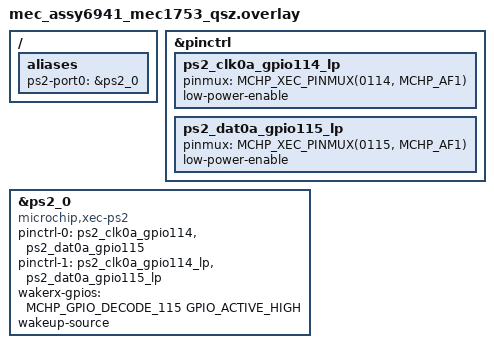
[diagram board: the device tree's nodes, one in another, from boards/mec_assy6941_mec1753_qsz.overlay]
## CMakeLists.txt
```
# SPDX-License-Identifier: Apache-2.0

cmake_minimum_required(VERSION 3.28.0)
find_package(Zephyr REQUIRED HINTS $ENV{ZEPHYR_BASE})
project(espi)

FILE(GLOB app_sources src/*.c)
target_sources(app PRIVATE ${app_sources})
```

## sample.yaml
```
sample:
  name: PS2 driver  sample
tests:
  sample.drivers.espi.ps2:
    tags:
      - drivers
      - ps2
    integration_platforms:
      - mec172xmodular_assy6930
    harness: console
    harness_config:
      type: multi_line
      ordered: true
      regex:
        - "mb data(.*)"
      fixture: fixture_connect_mouse
    filter: dt_compat_enabled("microchip,xec-ps2")
```

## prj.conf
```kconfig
CONFIG_STDOUT_CONSOLE=y
CONFIG_PRINTK=y
CONFIG_PS2=y
CONFIG_PM_DEVICE=y
CONFIG_PM=y
```

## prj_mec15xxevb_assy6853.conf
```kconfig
# PS2 + mec15xxevb_assy6853
CONFIG_CONSOLE=y
CONFIG_LOG=y
CONFIG_PS2=y
```

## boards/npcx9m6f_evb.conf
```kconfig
CONFIG_CONSOLE=y
CONFIG_LOG=y
```

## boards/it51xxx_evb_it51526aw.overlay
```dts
/*
 * Copyright (c) 2026 ITE Corporation. All Rights Reserved.
 *
 * SPDX-License-Identifier: Apache-2.0
 */

/ {
	aliases {
		ps2-port0 = &ps2_0;
	};
};

&ps2_0 {
	pinctrl-0 = <&ps2_0_clk_gph3_default &ps2_0_data_gph4_default>;
	pinctrl-names = "default";

	clk-gpios = <&gpioh 3 0>;
	data-gpios = <&gpioh 4 0>;

	status = "okay";
};
```

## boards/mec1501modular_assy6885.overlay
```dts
/*
 * Copyright (c) 2023 Microchip Technology Inc.
 *
 * SPDX-License-Identifier: Apache-2.0
 */

&ps2_0 {	/* PS2DAT0B */
	wakerx-gpios = <MCHP_GPIO_DECODE_010 GPIO_ACTIVE_HIGH>;
	wakeup-source;
};

&ps2_1 {	/* PS2DAT1B */
	wakerx-gpios = <MCHP_GPIO_DECODE_155 GPIO_ACTIVE_HIGH>;
	wakeup-source;
};

/ {
	aliases {
		ps2-port0 = &ps2_0;
	};
};
```

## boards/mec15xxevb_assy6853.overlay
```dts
/*
 * Copyright (c) 2023 Microchip Technology Inc.
 *
 * SPDX-License-Identifier: Apache-2.0
 */

&ps2_0 { /* PS2DAT0B */
	wakerx-gpios = <MCHP_GPIO_DECODE_010 GPIO_ACTIVE_HIGH>;
	wakeup-source;
};

&ps2_1 { /* PS2DAT1B */
	wakerx-gpios = <MCHP_GPIO_DECODE_155 GPIO_ACTIVE_HIGH>;
	wakeup-source;
};

/ {
	aliases {
		ps2-port0 = &ps2_0;
	};
};
```

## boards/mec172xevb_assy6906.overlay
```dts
/*
 * Copyright (c) 2023 Microchip Technology Inc.
 *
 * SPDX-License-Identifier: Apache-2.0
 */

&ps2_0 { /* PS2DAT0A */
	wakerx-gpios = <MCHP_GPIO_DECODE_115 GPIO_ACTIVE_HIGH>;
	wakeup-source;
};

/ {
	aliases {
		ps2-port0 = &ps2_0;
	};
};
```

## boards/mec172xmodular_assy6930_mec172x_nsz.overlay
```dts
/*
 * Copyright (c) 2023 Microchip Technology Inc.
 *
 * SPDX-License-Identifier: Apache-2.0
 */

/ {
	aliases {
		ps2-port0 = &ps2_0;
	};
};
```

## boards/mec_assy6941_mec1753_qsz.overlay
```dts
/*
 * Copyright (c) 2026 Microchip Technology Inc.
 *
 * SPDX-License-Identifier: Apache-2.0
 */

&pinctrl {
	ps2_clk0a_gpio114_lp: ps2_clk0a_gpio114_lp {
		pinmux = <MCHP_XEC_PINMUX(0114, MCHP_AF1)>;
		low-power-enable;
	};

	ps2_dat0a_gpio115_lp: ps2_dat0a_gpio115_lp {
		pinmux = <MCHP_XEC_PINMUX(0115, MCHP_AF1)>;
		low-power-enable;
	};
};

&ps2_0 { /* PS2DAT0A */
	compatible = "microchip,xec-ps2";
	pinctrl-0 = <&ps2_clk0a_gpio114 &ps2_dat0a_gpio115>;
	pinctrl-1 = <&ps2_clk0a_gpio114_lp &ps2_dat0a_gpio115_lp>;
	pinctrl-names = "default", "sleep";
	wakerx-gpios = <MCHP_GPIO_DECODE_115 GPIO_ACTIVE_HIGH>;
	wakeup-source;
	status = "okay";
};

/ {
	aliases {
		ps2-port0 = &ps2_0;
	};
};
```

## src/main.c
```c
/*
 * Copyright (c) 2019 Intel Corporation
 *
 * SPDX-License-Identifier: Apache-2.0
 */

#include <zephyr/kernel.h>
#include <zephyr/sys/printk.h>
#include <zephyr/drivers/ps2.h>
#include <soc.h>
#define LOG_LEVEL LOG_LEVEL_DBG
#include <zephyr/logging/log.h>
#define LOG_MODULE_NAME main

LOG_MODULE_REGISTER();

#define TASK_STACK_SIZE 1024
#define PRIORITY 7
/*Minimum safe time interval between regular PS/2 calls */
#define MS_BETWEEN_REGULAR_CALLS 8
/*Minimum safe time interval between BAT/Reset PS/2 calls */
#define MS_BETWEEN_RESET_CALLS 500

static void to_port_60_thread(void *dummy1, void *dummy2, void *dummy3);
static void saturate_ps2(struct k_timer *timer);
static bool host_blocked;

K_THREAD_DEFINE(aux_thread_id, TASK_STACK_SIZE, to_port_60_thread,
		NULL, NULL, NULL, PRIORITY, 0, 0);
K_SEM_DEFINE(p60_sem, 0, 1);
K_MSGQ_DEFINE(aux_to_host_queue, sizeof(uint8_t), 8, 4);

/* We use a timer to saturate the queue */
K_TIMER_DEFINE(block_ps2_timer, saturate_ps2, NULL);

static const struct device *const ps2_0_dev =
	DEVICE_DT_GET(DT_ALIAS(ps2_port0));

static void saturate_ps2_handler(struct k_work *work)
{
	ARG_UNUSED(work);

	LOG_DBG("block host\n");
	host_blocked = true;
	ps2_disable_callback(ps2_0_dev);
	k_sleep(K_MSEC(500));
	host_blocked = false;
	ps2_enable_callback(ps2_0_dev);
}

K_WORK_DEFINE(saturate_ps2_work, saturate_ps2_handler);

static void saturate_ps2(struct k_timer *timer)
{
	ARG_UNUSED(timer);

	k_work_submit(&saturate_ps2_work);
}

static void mb_callback(const struct device *dev, uint8_t value)
{
	if (k_msgq_put(&aux_to_host_queue, &value, K_NO_WAIT) != 0) {
		ps2_disable_callback(ps2_0_dev);
	}

	if (!host_blocked) {
		k_sem_give(&p60_sem);
	}
}

/* This data is sent to BIOS and eventually is consumed by the host OS */
static void to_port_60_thread(void *dummy1, void *dummy2, void *dummy3)
{
	uint8_t data;

	while (true) {
		k_sem_take(&p60_sem, K_FOREVER);
		while (!k_msgq_get(&aux_to_host_queue, &data, K_NO_WAIT)) {
			LOG_DBG("\nmb data :%02x\n", data);
		}
	}
}

/* Commands expected from BIOS and Windows */
void initialize_mouse(void)
{
	LOG_DBG("mouse->f4\n");
	ps2_write(ps2_0_dev, 0xf4);
	k_msleep(MS_BETWEEN_REGULAR_CALLS);
	LOG_DBG("Reset mouse->ff\n");
	ps2_write(ps2_0_dev, 0xff);
	k_msleep(MS_BETWEEN_RESET_CALLS);
	LOG_DBG("Reset mouse->ff\n");
	ps2_write(ps2_0_dev, 0xff);
	k_msleep(MS_BETWEEN_RESET_CALLS);
	LOG_DBG("Read ID mouse->f2\n");
	ps2_write(ps2_0_dev, 0xf2);
	k_msleep(MS_BETWEEN_REGULAR_CALLS);
	LOG_DBG("Set resolution mouse->e8\n");
	ps2_write(ps2_0_dev, 0xe8);
	k_msleep(MS_BETWEEN_REGULAR_CALLS);
	LOG_DBG("mouse->00\n");
	ps2_write(ps2_0_dev, 0x00);
	k_msleep(MS_BETWEEN_REGULAR_CALLS);
	LOG_DBG("Set scaling 1:1 mouse->e6\n");
	ps2_write(ps2_0_dev, 0xe6);
	k_msleep(MS_BETWEEN_REGULAR_CALLS);
	LOG_DBG("Set scaling 1:1 mouse->e6\n");
	ps2_write(ps2_0_dev, 0xe6);
	k_msleep(MS_BETWEEN_REGULAR_CALLS);
	LOG_DBG("Set scaling 1:1 mouse->e6\n");
	ps2_write(ps2_0_dev, 0xe6);
	k_msleep(MS_BETWEEN_REGULAR_CALLS);
	LOG_DBG("mouse->e9\n");
	ps2_write(ps2_0_dev, 0xe9);
	k_msleep(MS_BETWEEN_REGULAR_CALLS);
	LOG_DBG("Set resolution mouse->e8\n");
	ps2_write(ps2_0_dev, 0xe8);
	k_msleep(MS_BETWEEN_REGULAR_CALLS);
	LOG_DBG("8 Counts/mm mouse->0x03\n");
	ps2_write(ps2_0_dev, 0x03);
	k_msleep(MS_BETWEEN_REGULAR_CALLS);
	LOG_DBG("Set sample rate mouse->0xF3\n");
	ps2_write(ps2_0_dev, 0xf3);
	k_msleep(MS_BETWEEN_REGULAR_CALLS);
	LOG_DBG("decimal 200 ->0xc8\n");
	ps2_write(ps2_0_dev, 0xc8);
	k_msleep(MS_BETWEEN_REGULAR_CALLS);
	LOG_DBG("Set sample rate mouse->0xF3\n");
	ps2_write(ps2_0_dev, 0xf3);
	k_msleep(MS_BETWEEN_REGULAR_CALLS);
	LOG_DBG("decimal 100 ->0x64\n");
	ps2_write(ps2_0_dev, 0x64);
	LOG_DBG("Set sample rate mouse->0xF3\n");
	ps2_write(ps2_0_dev, 0xf3);
	k_msleep(MS_BETWEEN_REGULAR_CALLS);
	LOG_DBG("decimal 80 ->0x50\n");
	ps2_write(ps2_0_dev, 0x50);
	k_msleep(MS_BETWEEN_REGULAR_CALLS);
	LOG_DBG("Read device type->0xf2\n");
	ps2_write(ps2_0_dev, 0xf2);
	k_msleep(MS_BETWEEN_REGULAR_CALLS);
	LOG_DBG("Set sample rate mouse->0xF3\n");
	ps2_write(ps2_0_dev, 0xf3);
	k_msleep(MS_BETWEEN_REGULAR_CALLS);
	LOG_DBG("decimal 200 ->0xc8\n");
	ps2_write(ps2_0_dev, 0xc8);
	k_msleep(MS_BETWEEN_REGULAR_CALLS);
	LOG_DBG("Set sample rate mouse->0xF3\n");
	ps2_write(ps2_0_dev, 0xf3);
	k_msleep(MS_BETWEEN_REGULAR_CALLS);
	LOG_DBG("decimal 200 ->0xc8\n");
	ps2_write(ps2_0_dev, 0xc8);
	k_msleep(MS_BETWEEN_REGULAR_CALLS);
	LOG_DBG("Set sample rate mouse->0xF3\n");
	ps2_write(ps2_0_dev, 0xf3);
	k_msleep(MS_BETWEEN_REGULAR_CALLS);
	LOG_DBG("decimal 80 ->0x50\n");
	ps2_write(ps2_0_dev, 0x50);
	k_msleep(MS_BETWEEN_REGULAR_CALLS);
	LOG_DBG("Read device type->0xf2\n");
	ps2_write(ps2_0_dev, 0xf2);
	k_msleep(MS_BETWEEN_REGULAR_CALLS);
	LOG_DBG("Set sample rate mouse->0xF3\n");
	ps2_write(ps2_0_dev, 0xf3);
	k_msleep(MS_BETWEEN_REGULAR_CALLS);
	LOG_DBG("decimal 100 ->0x64\n");
	ps2_write(ps2_0_dev, 0x64);
	k_msleep(MS_BETWEEN_REGULAR_CALLS);
	LOG_DBG("Set resolution mouse->e8\n");
	ps2_write(ps2_0_dev, 0xe8);
	k_msleep(MS_BETWEEN_REGULAR_CALLS);
	LOG_DBG("8 Counts/mm mouse->0x03\n");
	ps2_write(ps2_0_dev, 0x03);
	k_msleep(MS_BETWEEN_REGULAR_CALLS);
	LOG_DBG("mouse->f4\n");
	ps2_write(ps2_0_dev, 0xf4);
	k_msleep(MS_BETWEEN_REGULAR_CALLS);
}

int main(void)
{
	printk("PS/2 test with mouse\n");
	/* Wait for the PS/2 BAT to finish */
	k_msleep(MS_BETWEEN_RESET_CALLS);

	/* The ps2 blocks are generic, therefore, it is allowed to swap
	 * keyboard and mouse as desired
	 */
	if (!device_is_ready(ps2_0_dev)) {
		printk("%s: device not ready.\n", ps2_0_dev->name);
		return 0;
	}
	ps2_config(ps2_0_dev, mb_callback);
	/*Make sure there is a PS/2 device connected */
	initialize_mouse();

	k_timer_start(&block_ps2_timer, K_SECONDS(2), K_SECONDS(1));
	return 0;
}
```
